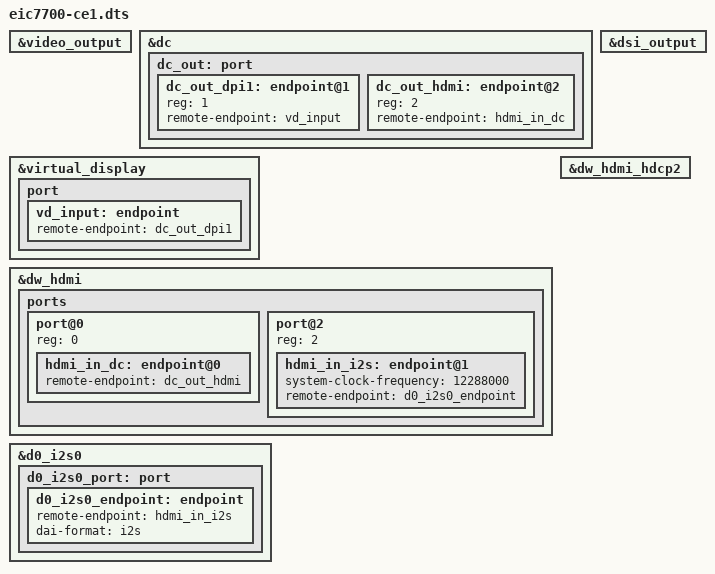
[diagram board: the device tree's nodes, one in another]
// SPDX-License-Identifier: GPL-2.0
/*
 * Device Tree file for Eswin EIC7700 SoC.
 *
 * Copyright 2024, Beijing ESWIN Computing Technology Co., Ltd.. All rights reserved.
 * SPDX-License-Identifier: GPL-2.0
 *
 * This program is free software: you can redistribute it and/or modify
 * it under the terms of the GNU General Public License as published by
 * the Free Software Foundation, version 2.
 *
 * This program is distributed in the hope that it will be useful,
 * but WITHOUT ANY WARRANTY; without even the implied warranty of
 * MERCHANTABILITY or FITNESS FOR A PARTICULAR PURPOSE.  See the
 * GNU General Public License for more details.
 *
 * You should have received a copy of the GNU General Public License
 * along with this program.  If not, see <https://www.gnu.org/licenses/>.
 */

/dts-v1/;
#include "eic7700-ce1.dtsi"

&video_output {
	status = "okay";
};

&dc {
	status = "okay";
	dc_out: port {
		#address-cells = <1>;
		#size-cells = <0>;
		dc_out_dpi1: endpoint@1 {
			reg = <1>;
			remote-endpoint = <&vd_input>;
		};
		dc_out_hdmi: endpoint@2 {
			reg = <2>;
			remote-endpoint = <&hdmi_in_dc>;
		};
	};
};

&virtual_display {
	status = "okay";
	port {
		vd_input: endpoint {
			remote-endpoint = <&dc_out_dpi1>;
		};
	};
};

&dsi_output {
	status = "okay";
};


&dw_hdmi {
	status = "okay";
	ports {
		#address-cells = <1>;
		#size-cells = <0>;
		port@0 {
			reg = <0>;
			hdmi_in_dc: endpoint@0 {
				remote-endpoint = <&dc_out_hdmi>;
			};
		};
		port@2 {
			reg = <2>;
			hdmi_in_i2s: endpoint@1 {
				system-clock-frequency = <12288000>;
				remote-endpoint = <&d0_i2s0_endpoint>;
			};
		};
	};
};

&dw_hdmi_hdcp2 {
    status = "okay";
};

&d0_i2s0 {
	status = "okay";
	d0_i2s0_port: port {
		d0_i2s0_endpoint: endpoint {
			remote-endpoint = <&hdmi_in_i2s>;
			dai-format = "i2s";
		};
	};
};

